# PIC16LF76 register map
Vendor: Microchip
Architecture 16xxxx. Special function registers and configuration words.
Registers are 8-bit, read-write, no defined reset value unless marked. A register's access mark holds for its fields unless they carry their own. Addresses are absolute, and some are shared; only a register's first bit layout is shown; lines under a group give offsets from that group; [hi:lo] are bit positions; {n}, {i} and the like mark numbered series; 'fields as' and 'values as' point back to an identical list; <NAME> marks a mode.

## Further device data
pins=1: MCLR/Vpp; 2: RA0/AN0; 3: RA1/AN1; 4: RA2/AN2; 5: RA3/AN3/Vref; 6: RA4/T0CKI; 7: RA5/SS/AN4; 8: Vss; 9: OSC1/CLKI; 10: OSC2/CLKO; 11: RC0/T1OSO/T1CKI; 12: RC1/T1OSI/CCP2; 13: RC2/CCP1; 14: RC3/SCK/SCL; 15: RC4/SDI/SDA; 16: RC5/SDO; 17: RC6/TX/CK; 18: RC7/RX/DT; 19: Vss; 20: Vdd; 21: RB0/INT; 22: RB1; 23: RB2; 24: RB3/PGM; 25: RB4; 26: RB5; 27: RB6/PGC; 28: RB7/PGD

## SFR
0x00 INDF access not given
0x01 TMR0 — (power-on value xxxxxxxx)
0x02 PCL reset 0x0
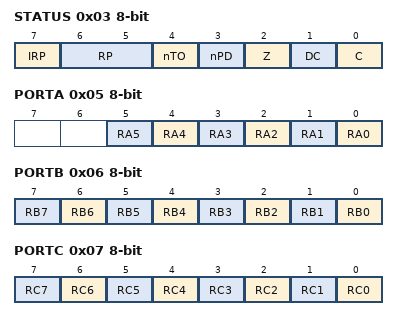
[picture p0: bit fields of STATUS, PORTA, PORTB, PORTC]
0x03 STATUS — (power-on value 00011xxx)
  [7] IRP, [6:5] RP, [4] nTO ro, [3] nPD ro, [2] Z, [1] DC, [0] C
0x04 FSR — (power-on value xxxxxxxx)
0x05 PORTA — (power-on value --0x0000)
  [n] RA{n} (n=0..5)
0x06 PORTB — (power-on value xxxxxxxx)
  [n] RB{n} (n=0..7)
0x07 PORTC — (power-on value xxxxxxxx)
  [n] RC{n} (n=0..7)
0x0A PCLATH reset 0x0
  [4:0] PCLATH
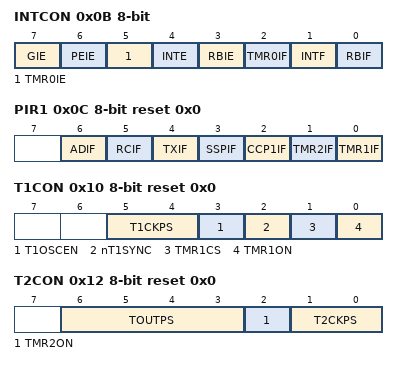
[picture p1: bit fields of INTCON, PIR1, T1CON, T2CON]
0x0B INTCON — (power-on value 0000000x)
  [7] GIE, [6] PEIE, [5] TMR0IE, [4] INTE, [3] RBIE, [2] TMR0IF, [1] INTF, [0] RBIF
0x0C PIR1 reset 0x0
  [6] ADIF, [5] RCIF ro, [4] TXIF ro, [3] SSPIF, [2] CCP1IF, [1] TMR2IF, [0] TMR1IF
0x0D PIR2 reset 0x0
  [0] CCP2IF
0x0E TMR1L — (power-on value xxxxxxxx)
0x0F TMR1H — (power-on value xxxxxxxx)
0x10 T1CON reset 0x0
  [5:4] T1CKPS, [3] T1OSCEN, [2] nT1SYNC, [1] TMR1CS, [0] TMR1ON
0x11 TMR2 reset 0x0
0x12 T2CON reset 0x0
  [6:3] TOUTPS, [2] TMR2ON, [1:0] T2CKPS
0x13 SSPBUF — (power-on value xxxxxxxx)
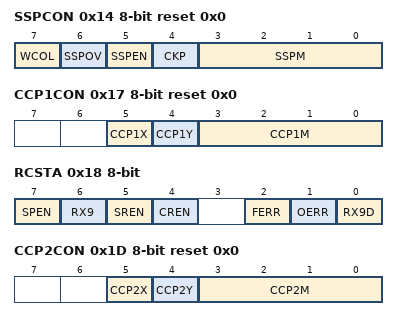
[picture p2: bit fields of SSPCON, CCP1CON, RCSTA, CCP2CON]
0x14 SSPCON reset 0x0
  [7] WCOL, [6] SSPOV, [5] SSPEN, [4] CKP, [3:0] SSPM
0x15 CCPR1L — (power-on value xxxxxxxx)
0x16 CCPR1H — (power-on value xxxxxxxx)
0x17 CCP1CON reset 0x0
  [5] CCP1X, [4] CCP1Y, [3:0] CCP1M
0x18 RCSTA — (power-on value 0000-00x)
  [7] SPEN, [6] RX9, [5] SREN, [4] CREN, [2] FERR ro, [1] OERR ro, [0] RX9D ro
0x19 TXREG reset 0x0
0x1A RCREG ro reset 0x0
0x1B CCPR2L — (power-on value xxxxxxxx)
0x1C CCPR2H — (power-on value xxxxxxxx)
0x1D CCP2CON reset 0x0
  [5] CCP2X, [4] CCP2Y, [3:0] CCP2M
0x1E ADRES — (power-on value xxxxxxxx)
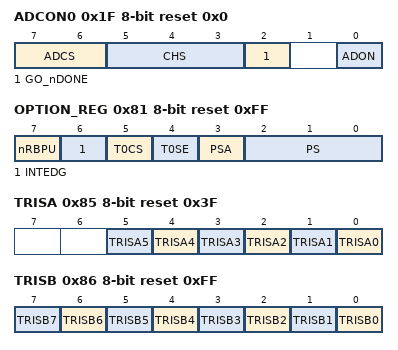
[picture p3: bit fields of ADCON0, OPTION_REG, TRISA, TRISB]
0x1F ADCON0 reset 0x0
  [7:6] ADCS, [5:3] CHS, [2] GO_nDONE, [0] ADON
0x81 OPTION_REG reset 0xFF
  [7] nRBPU, [6] INTEDG, [5] T0CS, [4] T0SE, [3] PSA, [2:0] PS
0x85 TRISA reset 0x3F
  [n] TRISA{n} (n=0..5)
0x86 TRISB reset 0xFF
  [n] TRISB{n} (n=0..7)
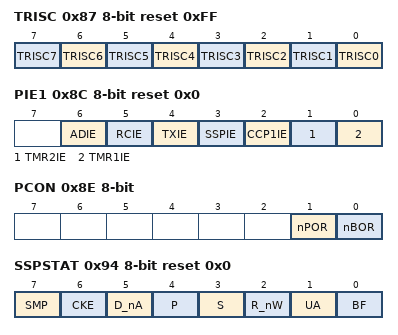
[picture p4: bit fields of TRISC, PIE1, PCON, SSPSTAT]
0x87 TRISC reset 0xFF
  [n] TRISC{n} (n=0..7)
0x8C PIE1 reset 0x0
  [6] ADIE, [5] RCIE, [4] TXIE, [3] SSPIE, [2] CCP1IE, [1] TMR2IE, [0] TMR1IE
0x8D PIE2 reset 0x0
  [0] CCP2IE
0x8E PCON — (power-on value ------qq)
  [1] nPOR, [0] nBOR
0x92 PR2 reset 0xFF
0x93 SSPADD reset 0x0
0x94 SSPSTAT reset 0x0
  [7] SMP, [6] CKE, [5] D_nA, [4] P, [3] S, [2] R_nW, [1] UA, [0] BF
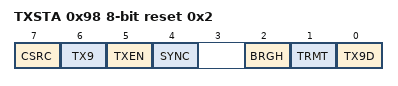
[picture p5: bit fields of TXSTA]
0x98 TXSTA reset 0x2
  [7] CSRC, [6] TX9, [5] TXEN, [4] SYNC, [2] BRGH, [1] TRMT ro, [0] TX9D
0x99 SPBRG reset 0x0
0x9F ADCON1 reset 0x0
  [2:0] PCFG
0x10C PMDATA — (power-on value xxxxxxxx)
0x10D PMADR — (power-on value xxxxxxxx)
0x10E PMDATH — (power-on value --xxxxxx)
  [5:0] PMDATH
0x10F PMADRH — (power-on value ---xxxxx)
  [4:0] PMADRH
0x18C PMCON1 reset 0x80
  [0] RD — (can only be set)

## CONFIG — Configuration words, addresses in ProgramSpace
0x2007 CONFIG 14-bit reset 0x3FFF
  [6] BOREN — Brown-out Reset Enable bit
    1=ON (BOR enabled); 0=OFF (BOR disabled)
  [4] CP — FLASH Program Memory Code Protection bit
    1=OFF (Code protection off); 0=ON (All Memory locations code protected)
  [3] PWRTE — Power-up Timer Enable bit
    1=OFF (PWRT disabled); 0=ON (PWRT enabled)
  [2] WDTE — Watchdog Timer Enable bit
    1=ON (WDT enabled); 0=OFF (WDT disabled)
  [1:0] FOSC — Oscillator Selection bits
    3=RC (RC oscillator); 2=HS (HS oscillator); 1=XT (XT oscillator); 0=LP (LP oscillator)
